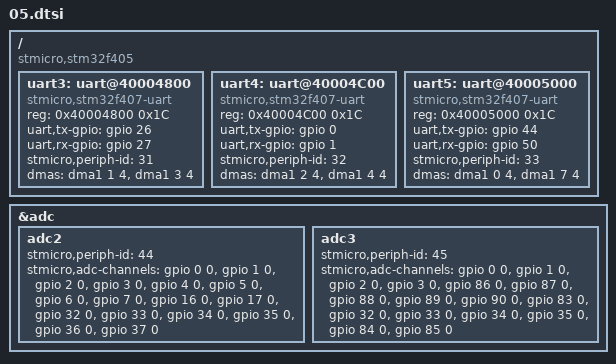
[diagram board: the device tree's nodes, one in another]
/include/ "common.dtsi"

/ {
    compatible = "stmicro,stm32f405", "stmicro,stm32f4";

    uart3: uart@40004800 {
        compatible = "stmicro,stm32f407-uart";
        reg = <0x40004800 0x1C>;
        uart,tx-gpio = <&gpio 26 0>;    /* PB10 */
        uart,rx-gpio = <&gpio 27 0>;    /* PB11 */
        stmicro,periph-id = <31>;       /* STM32F4_PERIPH_USART3 */
        dmas = <&dma1 1 4>, <&dma1 3 4>;
        dma-names = "rx", "tx";
    };

    uart4: uart@40004C00 {
        compatible = "stmicro,stm32f407-uart";
        reg = <0x40004C00 0x1C>;
        uart,tx-gpio = <&gpio 0 0>;     /* PA0 */
        uart,rx-gpio = <&gpio 1 0>;     /* PA1 */
        stmicro,periph-id = <32>;       /* STM32F4_PERIPH_USART4 */
        dmas = <&dma1 2 4>, <&dma1 4 4>;
        dma-names = "rx", "tx";
    };

    uart5: uart@40005000 {
        compatible = "stmicro,stm32f407-uart";
        reg = <0x40005000 0x1C>;
        uart,tx-gpio = <&gpio 44 0>;    /* PC12 */
        uart,rx-gpio = <&gpio 50 0>;    /* PD2 */
        stmicro,periph-id = <33>;       /* STM32F4_PERIPH_USART5 */
        dmas = <&dma1 0 4>, <&dma1 7 4>;
        dma-names = "rx", "tx";
    };
};

&adc {
    adc2 {
        stmicro,periph-id = <44>;   /* STM32F4_PERIPH_ADC2 */
        stmicro,adc-channels = <&gpio 0 0>  /* PA0 */,
                               <&gpio 1 0>  /* PA1 */,
                               <&gpio 2 0>  /* PA2 */,
                               <&gpio 3 0>  /* PA3 */,
                               <&gpio 4 0>  /* PA4 */,
                               <&gpio 5 0>  /* PA5 */,
                               <&gpio 6 0>  /* PA6 */,
                               <&gpio 7 0>  /* PA7 */,
                               <&gpio 16 0> /* PB0 */,
                               <&gpio 17 0> /* PB1 */,
                               <&gpio 32 0> /* PC0 */,
                               <&gpio 33 0> /* PC1 */,
                               <&gpio 34 0> /* PC2 */,
                               <&gpio 35 0> /* PC3 */,
                               <&gpio 36 0> /* PC4 */,
                               <&gpio 37 0> /* PC5 */;
    };

    adc3 {
        stmicro,periph-id = <45>;   /* STM32F4_PERIPH_ADC3 */
        stmicro,adc-channels = <&gpio 0 0>  /* PA0 */,
                               <&gpio 1 0>  /* PA1 */,
                               <&gpio 2 0>  /* PA2 */,
                               <&gpio 3 0>  /* PA3 */,
                               <&gpio 86 0> /* PF6 */,
                               <&gpio 87 0> /* PF7 */,
                               <&gpio 88 0> /* PF8 */,
                               <&gpio 89 0> /* PF9 */,
                               <&gpio 90 0> /* PF10 */,
                               <&gpio 83 0> /* PF3 */,
                               <&gpio 32 0> /* PC0 */,
                               <&gpio 33 0> /* PC1 */,
                               <&gpio 34 0> /* PC2 */,
                               <&gpio 35 0> /* PC3 */,
                               <&gpio 84 0> /* PF4 */,
                               <&gpio 85 0> /* PF5 */;
    };
};
